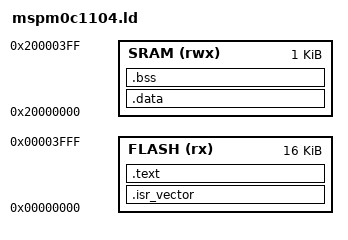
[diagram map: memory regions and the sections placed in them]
//Code generated by Claude 4.6 Sonnet (Anthropic), accessed April 2026.
//Prompt: "Write a linker script for the MSPM0C1104 (16K FLASH, 1K SRAM) with vector table, stack symbol, and .data/.bss sections."
//The code was reviewed and adapted by Hanseo Ryu.

/* Physical memory layout of MSPM0C1104 */
MEMORY
{
    FLASH (rx)  : ORIGIN = 0x00000000, LENGTH = 16K  /* read/execute only */
    SRAM  (rwx) : ORIGIN = 0x20000000, LENGTH = 1K   /* read/write/execute */
}

/* Stack grows downward from the top of SRAM */
_estack = ORIGIN(SRAM) + LENGTH(SRAM);

SECTIONS
{
    /* Interrupt vector table must be at the very start of FLASH.
       KEEP prevents the linker from discarding it as unreferenced. */
    .isr_vector : { KEEP(*(.isr_vector)) } > FLASH

    /* Code and read-only data.
       _sidata marks where .data's initial values are stored in FLASH. */
    .text :
    {
        *(.text*)
        *(.rodata*)
        _sidata = .;
    } > FLASH

    /* Initialized globals/statics: stored in FLASH (AT _sidata),
       copied to SRAM at startup by Reset_Handler. */
    .data : AT(_sidata)
    {
        _sdata = .;   /* SRAM destination start */
        *(.data*)
        _edata = .;   /* SRAM destination end */
    } > SRAM

    /* Zero-initialized globals/statics: no storage in FLASH (NOLOAD),
       zeroed out in SRAM at startup by Reset_Handler. */
    .bss (NOLOAD) :
    {
        _sbss = .;
        *(.bss*)
        *(COMMON)
        _ebss = .;
    } > SRAM
}
